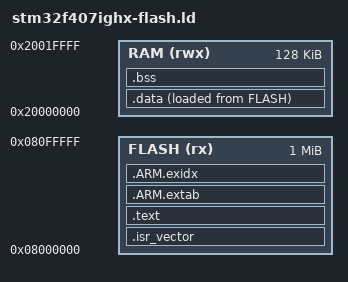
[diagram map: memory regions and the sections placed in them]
ENTRY(Reset_Handler)

MEMORY
{
  FLASH (rx)  : ORIGIN = 0x08000000, LENGTH = 1024K
  RAM   (rwx) : ORIGIN = 0x20000000, LENGTH = 128K
}

_estack = ORIGIN(RAM) + LENGTH(RAM);

SECTIONS
{
  .isr_vector :
  {
    . = ALIGN(4);
    KEEP(*(.isr_vector))
    . = ALIGN(4);
  } > FLASH

  .text :
  {
    . = ALIGN(4);
    *(.text*)
    *(.rodata*)
    KEEP(*(.init))
    KEEP(*(.fini))
    . = ALIGN(4);
    _etext = .;
  } > FLASH

  .ARM.extab : { *(.ARM.extab*) } > FLASH
  .ARM.exidx :
  {
    __exidx_start = .;
    *(.ARM.exidx*)
    __exidx_end = .;
  } > FLASH

  .data :
  {
    . = ALIGN(4);
    _sdata = .;
    *(.data*)
    . = ALIGN(4);
    _edata = .;
  } > RAM AT > FLASH
  _sidata = LOADADDR(.data);

  .bss (NOLOAD) :
  {
    . = ALIGN(4);
    _sbss = .;
    *(.bss*)
    *(COMMON)
    . = ALIGN(4);
    _ebss = .;
  } > RAM

  /DISCARD/ :
  {
    *(.comment)
    *(.note*)
  }
}

ASSERT(_ebss <= _estack, "STM32F407 RAM overflow")
